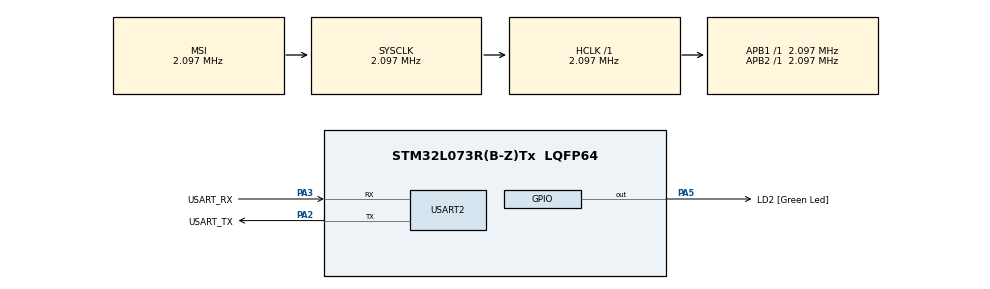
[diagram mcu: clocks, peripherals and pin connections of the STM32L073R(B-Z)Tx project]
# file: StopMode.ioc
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Mcu.Family=STM32L0
RCC.MSI_VALUE=2097000
PC15-OSC32_OUT.Mode=LSE-External-Oscillator
PH0-OSC_IN.Signal=RCC_OSC_IN
PA14.GPIO_Label=TCK
VP_RTC_VS_RTC_Activate.Mode=RTC_Enabled
PC14-OSC32_IN.Signal=RCC_OSC32_IN
ProjectManager.StackSize=0x400
NVIC.RTC_IRQn=true\:0\:0\:false\:false\:true\:true\:true
RTC.WakeUpClock-WakeUp=RTC_WAKEUPCLOCK_CK_SPRE_16BITS
PA3.Mode=Asynchronous
PA13.Signal=SYS_SWDIO
RCC.HSI16_VALUE=16000000
ProjectManager.TargetToolchain=STM32CubeIDE
RCC.APB2TimFreq_Value=2097000
PC15-OSC32_OUT.Signal=RCC_OSC32_OUT
RCC.AHBFreq_Value=2097000
PH0-OSC_IN.Mode=HSE-External-Clock-Source
PH0-OSC_IN.GPIO_Label=MCO
PA5.Signal=GPIO_Output
RCC.HSE_VALUE=8000000
board=NUCLEO-L073RZ
USART2.VirtualMode-Asynchronous=VM_ASYNC
RCC.VCOOutputFreq_Value=48000000
RCC.APB2Freq_Value=2097000
PC14-OSC32_IN.Mode=LSE-External-Oscillator
PA14.Mode=Serial_Wire
PA13.Mode=Serial_Wire
Mcu.Name=STM32L073R(B-Z)Tx
PA2.Signal=USART2_TX
PA13.GPIO_Label=TMS
RCC.SYSCLKFreq_VALUE=2097000
Mcu.Package=LQFP64
PA5.GPIO_Label=LD2 [Green Led]
PA2.GPIO_Label=USART_TX
PA14.Signal=SYS_SWCLK
ProjectManager.HeapSize=0x200
RCC.HSI_VALUE=16000000
VP_RTC_VS_RTC_WakeUp_intern.Mode=WakeUp
RCC.APB1TimFreq_Value=2097000
PA2.Mode=Asynchronous
RCC.APB1Freq_Value=2097000
RCC.HSI48_VALUE=48000000
PA3.GPIO_Label=USART_RX
PA3.Signal=USART2_RX

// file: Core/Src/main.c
/* USER CODE BEGIN Header */
/**
  ******************************************************************************
  * @file           : main.c
  * @brief          : Main program body
  ******************************************************************************
  * @attention
  *
  * <h2><center>&copy; Copyright (c) 2021 STMicroelectronics.
  * All rights reserved.</center></h2>
  *
  * This software component is licensed by ST under BSD 3-Clause license,
  * the "License"; You may not use this file except in compliance with the
  * License. You may obtain a copy of the License at:
  *                        opensource.org/licenses/BSD-3-Clause
  *
  ******************************************************************************
  */
/* USER CODE END Header */
#include "main.h"

/* USER CODE BEGIN Includes */
#include "string.h"
/* USER CODE END Includes */

RTC_HandleTypeDef hrtc;

UART_HandleTypeDef huart2;

void SystemClock_Config(void);
static void MX_GPIO_Init(void);
static void MX_USART2_UART_Init(void);
static void MX_RTC_Init(void);

/* USER CODE BEGIN 0 */
void HAL_GPIO_EXTI_Callback(uint16_t GPIO_PIN){
	if (GPIO_PIN ==GPIO_PIN_13) {

		  SystemClock_Config();
		  HAL_ResumeTick();
		  char *str2 = "Wakeup frOm stop mode with EXTII \n\n";
		  HAL_UART_Transmit(&huart2, (uint8_t*) str2 , strlen(str2), HAL_MAX_DELAY);
	}
}

void HAL_RTCEx_WakeUpTimerEventCallback(RTC_HandleTypeDef *hrtc){
	SystemClock_Config();
	HAL_ResumeTick();
	char *str2 = "Wakeup frOm stop mode with CLOCK \n\n";
	HAL_UART_Transmit(&huart2, (uint8_t*) str2 , strlen(str2), HAL_MAX_DELAY);
	HAL_PWR_DisableSleepOnExit();
}
/* USER CODE END 0 */

int main(void)
{

  /* MCU Configuration--------------------------------------------------------*/

  /* Reset of all peripherals, Initializes the Flash interface and the Systick. */
  HAL_Init();

  /* Configure the system clock */
  SystemClock_Config();

  /* Initialize all configured peripherals */
  MX_GPIO_Init();
  MX_USART2_UART_Init();
  MX_RTC_Init();
  /* USER CODE BEGIN 2 */
  uint8_t var = 5;
  for (var = 0; var < 20; ++var) {
	  HAL_GPIO_TogglePin(GPIOA, GPIO_PIN_5);
	  HAL_Delay(300);
  }

//  for (var = 0; var < 5; ++var) {
//	  HAL_GPIO_TogglePin(GPIOA, GPIO_PIN_5);
//	  HAL_Delay(2000);
//  }
//  char *str2 = "Wakeup frOm stop mode IN MAIN \n\n";
//  HAL_UART_Transmit(&huart2, (uint8_t*) str2 , strlen(str2), HAL_MAX_DELAY);
  /* USER CODE END 2 */

  /* Infinite loop */
  /* USER CODE BEGIN WHILE */
  while (1)
  {
	  char *str = "About to going into Stop Mode \n\n";
	  HAL_UART_Transmit(&huart2, (uint8_t*) str , strlen(str), HAL_MAX_DELAY);
	//  0x5A55

	  if (HAL_RTCEx_SetWakeUpTimer_IT(&hrtc,60 , RTC_WAKEUPCLOCK_CK_SPRE_16BITS) != HAL_OK)
	  {
	    Error_Handler();
	  }
	  HAL_SuspendTick();
	  HAL_PWR_DisableSleepOnExit();
	  HAL_PWR_EnterSTOPMode(PWR_LOWPOWERREGULATOR_ON, PWR_STOPENTRY_WFI);

	  HAL_RTCEx_DeactivateWakeUpTimer(&hrtc);
    /* USER CODE END WHILE */

  }
}

void SystemClock_Config(void)
{
  RCC_OscInitTypeDef RCC_OscInitStruct = {0};
  RCC_ClkInitTypeDef RCC_ClkInitStruct = {0};
  RCC_PeriphCLKInitTypeDef PeriphClkInit = {0};

  /** Configure the main internal regulator output voltage
  */
  __HAL_PWR_VOLTAGESCALING_CONFIG(PWR_REGULATOR_VOLTAGE_SCALE1);
  /** Initializes the RCC Oscillators according to the specified parameters
  * in the RCC_OscInitTypeDef structure.
  */
  RCC_OscInitStruct.OscillatorType = RCC_OSCILLATORTYPE_LSI|RCC_OSCILLATORTYPE_MSI;
  RCC_OscInitStruct.LSIState = RCC_LSI_ON;
  RCC_OscInitStruct.MSIState = RCC_MSI_ON;
  RCC_OscInitStruct.MSICalibrationValue = 0;
  RCC_OscInitStruct.MSIClockRange = RCC_MSIRANGE_5;
  RCC_OscInitStruct.PLL.PLLState = RCC_PLL_NONE;
  if (HAL_RCC_OscConfig(&RCC_OscInitStruct) != HAL_OK)
  {
    Error_Handler();
  }
  /** Initializes the CPU, AHB and APB buses clocks
  */
  RCC_ClkInitStruct.ClockType = RCC_CLOCKTYPE_HCLK|RCC_CLOCKTYPE_SYSCLK
                              |RCC_CLOCKTYPE_PCLK1|RCC_CLOCKTYPE_PCLK2;
  RCC_ClkInitStruct.SYSCLKSource = RCC_SYSCLKSOURCE_MSI;
  RCC_ClkInitStruct.AHBCLKDivider = RCC_SYSCLK_DIV1;
  RCC_ClkInitStruct.APB1CLKDivider = RCC_HCLK_DIV1;
  RCC_ClkInitStruct.APB2CLKDivider = RCC_HCLK_DIV1;

  if (HAL_RCC_ClockConfig(&RCC_ClkInitStruct, FLASH_LATENCY_0) != HAL_OK)
  {
    Error_Handler();
  }
  PeriphClkInit.PeriphClockSelection = RCC_PERIPHCLK_USART2|RCC_PERIPHCLK_RTC;
  PeriphClkInit.Usart2ClockSelection = RCC_USART2CLKSOURCE_PCLK1;
  PeriphClkInit.RTCClockSelection = RCC_RTCCLKSOURCE_LSI;
  if (HAL_RCCEx_PeriphCLKConfig(&PeriphClkInit) != HAL_OK)
  {
    Error_Handler();
  }
}

static void MX_RTC_Init(void)
{

  /** Initialize RTC Only
  */
  hrtc.Instance = RTC;
  hrtc.Init.HourFormat = RTC_HOURFORMAT_24;
  hrtc.Init.AsynchPrediv = 127;
  hrtc.Init.SynchPrediv = 255;
  hrtc.Init.OutPut = RTC_OUTPUT_DISABLE;
  hrtc.Init.OutPutRemap = RTC_OUTPUT_REMAP_NONE;
  hrtc.Init.OutPutPolarity = RTC_OUTPUT_POLARITY_HIGH;
  hrtc.Init.OutPutType = RTC_OUTPUT_TYPE_OPENDRAIN;
  if (HAL_RTC_Init(&hrtc) != HAL_OK)
  {
    Error_Handler();
  }
  /** Enable the WakeUp
  */
  if (HAL_RTCEx_SetWakeUpTimer_IT(&hrtc, 0, RTC_WAKEUPCLOCK_CK_SPRE_16BITS) != HAL_OK)
  {
    Error_Handler();
  }

}

static void MX_USART2_UART_Init(void)
{

  huart2.Instance = USART2;
  huart2.Init.BaudRate = 115200;
  huart2.Init.WordLength = UART_WORDLENGTH_8B;
  huart2.Init.StopBits = UART_STOPBITS_1;
  huart2.Init.Parity = UART_PARITY_NONE;
  huart2.Init.Mode = UART_MODE_TX_RX;
  huart2.Init.HwFlowCtl = UART_HWCONTROL_NONE;
  huart2.Init.OverSampling = UART_OVERSAMPLING_16;
  huart2.Init.OneBitSampling = UART_ONE_BIT_SAMPLE_DISABLE;
  huart2.AdvancedInit.AdvFeatureInit = UART_ADVFEATURE_NO_INIT;
  if (HAL_UART_Init(&huart2) != HAL_OK)
  {
    Error_Handler();
  }

}

static void MX_GPIO_Init(void)
{
  GPIO_InitTypeDef GPIO_InitStruct = {0};

  /* GPIO Ports Clock Enable */
  __HAL_RCC_GPIOC_CLK_ENABLE();
  __HAL_RCC_GPIOH_CLK_ENABLE();
  __HAL_RCC_GPIOA_CLK_ENABLE();

  /*Configure GPIO pin Output Level */
  HAL_GPIO_WritePin(LD2_GPIO_Port, LD2_Pin, GPIO_PIN_RESET);

  /*Configure GPIO pin : LD2_Pin */
  GPIO_InitStruct.Pin = LD2_Pin;
  GPIO_InitStruct.Mode = GPIO_MODE_OUTPUT_PP;
  GPIO_InitStruct.Pull = GPIO_NOPULL;
  GPIO_InitStruct.Speed = GPIO_SPEED_FREQ_LOW;
  HAL_GPIO_Init(LD2_GPIO_Port, &GPIO_InitStruct);

}

void Error_Handler(void)
{
  __disable_irq();
  while (1)
  {
  }
}

/************************ (C) COPYRIGHT STMicroelectronics *****END OF FILE****/
